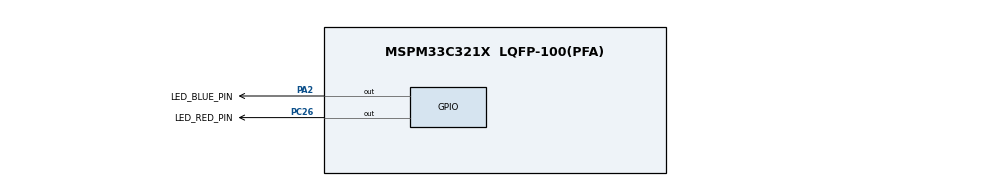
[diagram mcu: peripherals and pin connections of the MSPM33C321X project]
/**
 * @cliArgs --device "MSPM33C321X" --part "Default" --package "LQFP-100(PFA)" --product "mspm33_sdk@1.02.00.00"
 * @versions {"tool":"1.26.0+4407"}
 */
// @cliArgs --board /ti/boards/LP_MSPM33C321A --rtos nortos

/**
 * Import the modules used in this configuration.
 */
const GPIO          = scripting.addModule("/ti/driverlib/GPIO", {}, false);
const GPIO1         = GPIO.addInstance();
const GPIO2         = GPIO.addInstance();
const GPIO3         = GPIO.addInstance();
const HSADC         = scripting.addModule("/ti/driverlib/HSADC", {}, false);
const HSADC1        = HSADC.addInstance();
const SYSCTL        = scripting.addModule("/ti/driverlib/SYSCTL");
const TIMER         = scripting.addModule("/ti/driverlib/TIMER", {}, false);
const TIMER1        = TIMER.addInstance();
const ProjectConfig = scripting.addModule("/ti/project_config/ProjectConfig");

/**
 * Write custom configuration values to the imported modules.
 */
GPIO1.$name                               = "LED_BLUE";
GPIO1.associatedPins[0].$name             = "LED_BLUE_PIN";
GPIO1.associatedPins[0].launchPadShortcut = "LED2BlueEn";
GPIO1.associatedPins[0].pin.$assign       = "PA2";

const Board = scripting.addModule("/ti/driverlib/Board", {}, false);

GPIO2.$name                               = "LED_GREEN";
GPIO2.associatedPins[0].$name             = "LED_GREEN_PIN";
GPIO2.associatedPins[0].launchPadShortcut = "LED2GreenEn";

GPIO3.$name                               = "LED_RED";
GPIO3.associatedPins[0].$name             = "LED_RED_PIN";
GPIO3.associatedPins[0].launchPadShortcut = "LED2RedEn";
GPIO3.associatedPins[0].pin.$assign       = "PC26";

HSADC1.$name                          = "HSADC0";
HSADC1.enabledSOCs                    = ["ADC_SOC_NUMBER0"];
HSADC1.enabledInts                    = ["ADC_INT_NUMBER_1"];
HSADC1.enableInterrupt1               = true;
HSADC1.enableInterrupt1ContinuousMode = true;
HSADC1.interruptPulseMode             = "ADC_PULSE_END_OF_CONV";
HSADC1.soc0Channel                    = "ADC_CH_ADCIN_10";
HSADC1.enabledSEQs                    = ["ADC_SEQ_NUMBER1"];
HSADC1.seqPreemptMode                 = "ADC_PREEMPT_RESTART";
HSADC1.seq1Enable                     = true;
HSADC1.ADCsubscriber1Channel          = 1;
HSADC1.seq1TriggerSel                 = "ADC_TRIGGER_GEN_SUB_0";
HSADC1.peripheral.$assign             = "ADC0";


TIMER1.$name                       = "TIMER_0";
TIMER1.timerMode                   = "PERIODIC_UP";
TIMER1.timerClkDiv                 = 8;
TIMER1.timerClkPrescale            = 100;
TIMER1.event1PublisherChannel      = 1;
TIMER1.timerStartTimer             = true;
TIMER1.event1ControllerInterruptEn = ["ZERO_EVENT"];
TIMER1.timerPeriod                 = "30.3 ms";
TIMER1.peripheral.$assign          = "TIMA0_0";

ProjectConfig.genLibCMSIS        = true;
ProjectConfig.migrationCondition = true;

/**
 * Pinmux solution for unlocked pins/peripherals. This ensures that minor changes to the automatic solver in a future
 * version of the tool will not impact the pinmux you originally saw.  These lines can be completely deleted in order to
 * re-solve from scratch.
 */
Board.peripheral.$suggestSolution            = "DEBUGSS";
Board.peripheral.swclkPin.$suggestSolution   = "PA20";
Board.peripheral.swdioPin.$suggestSolution   = "PA19";
GPIO2.associatedPins[0].pin.$suggestSolution = "PC27";
SYSCTL.peripheral.$suggestSolution           = "SYSCTL";
